# LPC111x/LPC11Cxx/LPC11xxL/LPC11xxXL register map
File version: 6
CPU: CM0 r0p0, little endian, no MPU, no FPU, 2 interrupt priority bits
Registers are 32-bit, read-write, reset 0x0 unless marked. A register's access mark holds for its fields unless they carry their own. Offsets are from the block's base; [hi:lo] are bit positions; {n}, {i} and the like mark numbered series; 'fields as' and 'values as' point back to an identical list.

## I2C — Inter-Integrated Circuit (I²C) Controller
Base 0x40000000
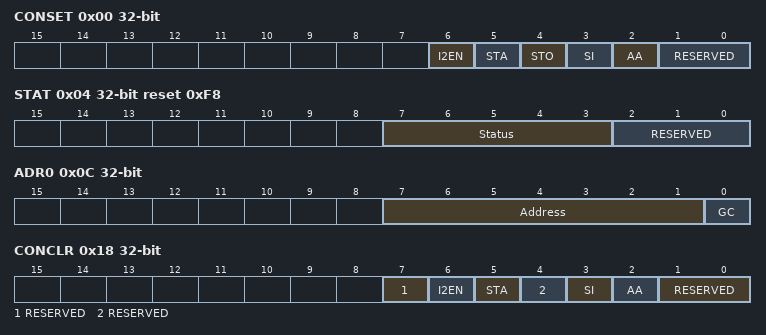
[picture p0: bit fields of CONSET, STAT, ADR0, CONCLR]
0x00 CONSET — I2C Control Set Register.
  [6] I2EN — I2C Interface Enable bit.
    1=ENABLE (Enable the I2C interface)
  [5] STA — START flag.
    1=SET (Set the flag)
  [4] STO — STOP flag.
    1=SET (Set the flag)
  [3] SI — Interrupt flag.
    1=SET (Set the flag)
  [2] AA — Assert Acknowledge flag.
    1=SET (Set the flag)
  [1:0] RESERVED — Reserved. User software should not write ones to reserved bits. The value read from a reserved bit is not defined.
0x04 STAT ro reset 0xF8 — I2C Status Register. During I2C operation, this register provides detailed status codes that allow software to determine the next action needed
  [7:3] Status — These bits give the actual status information about the I2C interface.
    0=BUS_ERROR (Bus error during an I2C serial transfer.); 1=START_CONDITION_TRANSMITTED (A START condition has been transmitted.); 2=REPEATED_START_CONDITION_TRANSMITTED (A Repeated START condition has been transmitted.); 3=WRITE_ADDRESS_TRANSMITTED_ACK (SLA+W has been transmitted; ACK has been received.); 4=WRITE_ADDRESS_TRANSMITTED_NOT_ACK (SLA+W has been transmitted; NOT ACK has been received.); 5=DATA_BYTE_TRANSMITTED_ACK (Data byte in DAT has been transmitted; ACK has been received.); 6=DATA_BYTE_TRANSMITTED_NOT_ACK (Data byte in DAT has been transmitted; NOT ACK has been received.); 7=ARBITRATION_LOST (In Master Transmitter mode, arbitration lost in SLA+R/W or Data bytes. In Master Receiver mode, arbitration lost in NOT ACK bit.); 8=READ_ADDRESS_TRANSMITTED_ACK (SLA+R has been transmitted; ACK has been received.); 9=READ_ADDRESS_TRANSMITTED_NOT_ACK (SLA+R has been transmitted; NOT ACK has been received.); 10=DATA_BYTE_RECEIVED_ACK (Data byte has been received; ACK has been returned.); 11=DATA_BYTE_RECEIVED_NOT_ACK (Data byte has been received; NOT ACK has been returned.); 12=OWN_WRITE_ADDRESS_RECEIVED_ACK (Own SLA+W has been received; ACK has been returned.); 13=ARBITRATION_LOST_OWN_WRITE_ADDRESS_RECEIVED_ACK (Arbitration lost in SLA+R/W as master; Own SLA+W has been received, ACK returned.); 14=GENERAL_CALL_RECEIVED_ACK (General call address (0x00) has been received; ACK has been returned.); 15=ARBITRATION_LOST_GENERAL_CALL_RECEIVED_ACK (Arbitration lost in SLA+R/W as master; General call address has been received; ACK has been returned.); 16=OWN_WRITE_ADDRESS_DATA_BYTE_RECEIVED_ACK (Previously addressed with own SLV address; Data byte has been received; ACK has been returned.); 17=OWN_WRITE_ADDRESS_DATA_BYTE_RECEIVED_NOT_ACK (Previously addressed with own SLV address; Data byte has been received; NOT ACK has been returned.); 18=GENERAL_CALL_DATA_BYTE_RECEIVED_ACK (Previously addressed with General Call; Data byte has been received; ACK has been returned.); 19=GENERAL_CALL_DATA_BYTE_RECEIVED_NOT_ACK (Previously addressed with General Call; Data byte has been received; NOT ACK has been returned.); 20=STOP_OR_REPEATED_START_CONDITION_RECEIVED_WHILE_ADDRESSED (A STOP condition or Repeated START condition has been received while still addressed as SLV/REC or SLV/TRX.); 21=OWN_READ_ADDRESS_ACK (Own SLA+R has been received; ACK has been returned.); 22=ARBITRATION_LOST_OWN_READ_ADDRESS_RECEIVED_ACK (Arbitration lost in SLA+R/W as master; Own SLA+R has been received; ACK has been returned.); 23=SLAVE_DATA_BYTE_TRANSMITTED_ACK (Data byte in DAT has been transmitted; ACK has been received.); 24=SLAVE_DATA_BYTE_TRANSMITTED_NOT_ACK (Data byte in DAT has been transmitted; NOT ACK has been received.); 25=LAST_DATA_BYTE_TRANSMITTED_ACK_RECEIVED (Last data byte in DAT has been transmitted (AA = 0); ACK has been received.); 31=NOT_AVAILABLE (There is no information available yet.)
  [2:0] RESERVED — These bits are unused and are always 0.
0x08 DAT — I2C Data Register. During master or slave transmit mode, data to be transmitted is written to this register. During master or slave receive mode, data that has been received may be read from this register
  [7:0] Data — Data values that have been received or are to be transmitted.
0x0C ADR0 — I2C Slave Address Register 0. Contains the 7-bit slave address for operation of the I2C interface in slave mode, and is not used in master mode. The least significant bit determines whether a slave responds to the General Call address
  [7:1] Address — The I2C device address for slave mode.
  [0] GC — General Call enable bit.
0x10 SCLH reset 0x4 — SCH Duty Cycle Register High Half Word. Determines the high time of the I2C clock
  [15:0] SCLH — Count for SCL HIGH time period selection.
0x14 SCLL reset 0x4 — SCL Duty Cycle Register Low Half Word. Determines the low time of the I2C clock. I2nSCLL and I2nSCLH together determine the clock frequency generated by an I2C master and certain times used in slave mode
  [15:0] SCLL — Count for SCL low time period selection.
0x18 CONCLR wo reset not defined — I2C Control Clear Register.
  [7] RESERVED — Reserved. User software should not write ones to reserved bits. The value read from a reserved bit is not defined.
  [6] I2EN — I2C Interface Disable bit.
    1=DISABLE (Disable the I2C interface)
  [5] STA — START flag.
    1=CLEAR (Clear the flag)
  [4] RESERVED — Reserved. User software should not write ones to reserved bits. The value read from a reserved bit is not defined.
  [3] SI — Interrupt flag.
    1=CLEAR (Clear the flag)
  [2] AA — Assert Acknowledge flag.
    1=CLEAR (Clear the flag)
  [1:0] RESERVED — Reserved. User software should not write ones to reserved bits. The value read from a reserved bit is not defined.
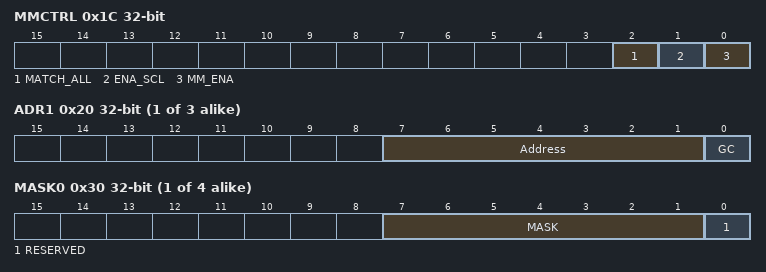
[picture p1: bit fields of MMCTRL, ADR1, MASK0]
0x1C MMCTRL — Monitor mode control register
  [2] MATCH_ALL — Select interrupt register match.
    0=MATCH (When this bit is cleared, an interrupt will only be generated when a match occurs to one of the (up-to) four address registers described above. That is, the module will respond as a normal slave as far as address-recognition is concerned); 1=ANYADDRESS (When this bit is set to 1 and the I2C is in monitor mode, an interrupt will be generated on ANY address received. This will enable the part to monitor all traffic on the bus)
  [1] ENA_SCL — SCL output enable.
    0=HIGH (When this bit is cleared to 0, the SCL output will be forced high when the module is in monitor mode. As described above, this will prevent the module from having any control over the I2C clock line); 1=NORMAL (When this bit is set, the I2C module may exercise the same control over the clock line that it would in normal operation. This means that, acting as a slave peripheral, the I2C module can stretch the clock line (hold it low) until it has had time to respond to an I2C interrupt.)
  [0] MM_ENA — Monitor mode enable.
    0=MONITOR_MODE_DISABLE (Monitor mode disabled); 1=THE_I2C_MODULE_WILL_ (The I2C module will enter monitor mode. In this mode the SDA output will be forced high. This will prevent the I2C module from outputting data of any kind (including ACK) onto the I 2C data bus. Depending on the state of the ENA_SCL bit, the output may be also forced high, preventing the module from having control over the I2C clock line)
{0x1C+4i} ADR{i} (i=1..3) — I2C Slave Address Register 1. Contains the 7-bit slave address for operation of the I2C interface in slave mode, and is not used in master mode. The least significant bit determines whether a slave responds to the General Call address
  fields as ADR0
0x2C DATA_BUFFER ro — Data buffer register. The contents of the 8 MSBs of the I2DAT shift register will be transferred to the DATA_BUFFER automatically after every nine bits (8 bits of data plus ACK or NACK) has been received on the bus
  [7:0] Data — This register holds contents of the 8 MSBs of the DAT shift register.
{0x30+4i} MASK{i} (i=0..3) — I2C Slave address mask register 0. This mask register is associated with I2ADR0 to determine an address match. The mask register has no effect when comparing to the General Call address (0000000)
  [7:1] MASK — Mask bits.
  [0] RESERVED — Reserved. User software should not write ones to reserved bits. This bit reads always back as 0.
